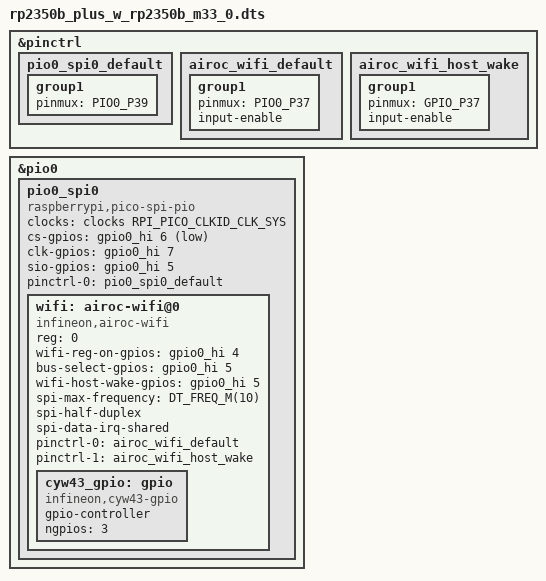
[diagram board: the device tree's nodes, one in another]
/*
 * SPDX-FileCopyrightText: Copyright (c) 2024 Andrew Featherstone
 * SPDX-FileCopyrightText: Copyright (c) 2026 Matheus de Alencar
 *
 * SPDX-License-Identifier: Apache-2.0
 */

/dts-v1/;

/* The build system assumes that there's a cpucluster-specific file.
 *
 * This file provides composition of the device tree:
 * 1. The common features of the SoC
 * 2. Core-specific configuration.
 * 3. Board-specific configuration.
 */
#include <raspberrypi/rpi_pico/rp2350b.dtsi>
#include <raspberrypi/rpi_pico/m33.dtsi>
#include "rp2350b_plus_w.dtsi"

&pinctrl {
	pio0_spi0_default: pio0_spi0_default {
		group1 {
			pinmux = <PIO0_P39>;
		};
	};

	airoc_wifi_default: airoc_wifi_default {
		group1 {
			pinmux = <PIO0_P37>;
			input-enable;
		};
	};

	airoc_wifi_host_wake: airoc_wifi_host_wake {
		group1 {
			pinmux = <GPIO_P37>;
			input-enable;
		};
	};
};

&pio0 {
	status = "okay";

	pio0_spi0: pio0_spi0 {
		compatible = "raspberrypi,pico-spi-pio";
		clocks = <&clocks RPI_PICO_CLKID_CLK_SYS>;
		#address-cells = <1>;
		#size-cells = <0>;
		cs-gpios = <&gpio0_hi 6 GPIO_ACTIVE_LOW>;
		clk-gpios = <&gpio0_hi 7 GPIO_ACTIVE_HIGH>;
		sio-gpios = <&gpio0_hi 5 GPIO_ACTIVE_HIGH>;
		pinctrl-0 = <&pio0_spi0_default>;
		pinctrl-names = "default";
		status = "okay";

		wifi: airoc-wifi@0 {
			compatible = "infineon,airoc-wifi";
			reg = <0>;
			wifi-reg-on-gpios = <&gpio0_hi 4 GPIO_ACTIVE_HIGH>;
			bus-select-gpios = <&gpio0_hi 5 GPIO_ACTIVE_HIGH>;
			wifi-host-wake-gpios = <&gpio0_hi 5 GPIO_ACTIVE_HIGH>;
			spi-max-frequency = <DT_FREQ_M(10)>;
			spi-half-duplex;
			spi-data-irq-shared;
			pinctrl-0 = <&airoc_wifi_default>;
			pinctrl-1 = <&airoc_wifi_host_wake>;
			pinctrl-names = "default", "host_wake";
			status = "okay";

			cyw43_gpio: gpio {
				compatible = "infineon,cyw43-gpio";
				gpio-controller;
				#gpio-cells = <2>;
				ngpios = <3>;
			};
		};
	};
};
